# ATmega32C1 register map
Vendor: Atmel; File version: 1.0
CPU: other r0p0, little endian, no MPU, no FPU, 4 interrupt priority bits
Registers are 8-bit, read-write, reset 0x0 unless marked. A register's access mark holds for its fields unless they carry their own. Offsets are from the block's base; [hi:lo] are bit positions; {n}, {i} and the like mark numbered series.

## PORTB — I/O Port
Base 0x00000023
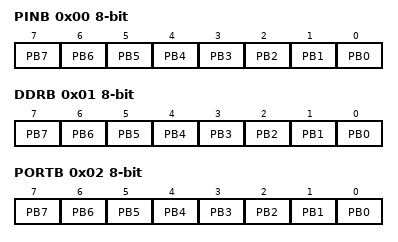
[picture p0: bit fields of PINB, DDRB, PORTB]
0x00 PINB — Port B Input Pins
  [n] PB{n} (n=0..7) — Pin B{n}
0x01 DDRB — Port B Data Direction Register
  [n] PB{n} (n=0..7) — Pin B{n}
0x02 PORTB — Port B Data Register
  [n] PB{n} (n=0..7) — Pin B{n}

## PORTC — I/O Port
Base 0x00000026
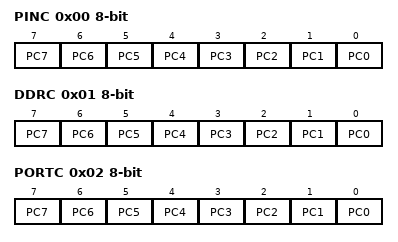
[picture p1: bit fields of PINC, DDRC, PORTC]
0x00 PINC — Port C Input Pins
  [n] PC{n} (n=0..7) — Pin C{n}
0x01 DDRC — Port C Data Direction Register
  [n] PC{n} (n=0..7) — Pin C{n}
0x02 PORTC — Port C Data Register
  [n] PC{n} (n=0..7) — Pin C{n}

## PORTD — I/O Port
Base 0x00000029
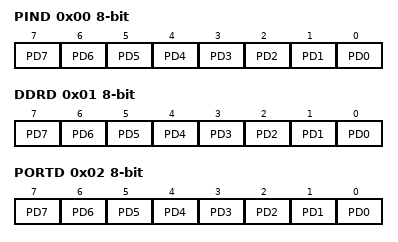
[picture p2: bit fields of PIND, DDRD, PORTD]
0x00 PIND — Port D Input Pins
  [n] PD{n} (n=0..7) — Pin D{n}
0x01 DDRD — Port D Data Direction Register
  [n] PD{n} (n=0..7) — Pin D{n}
0x02 PORTD — Port D Data Register
  [n] PD{n} (n=0..7) — Pin D{n}

## PORTE — I/O Port
Base 0x0000002C
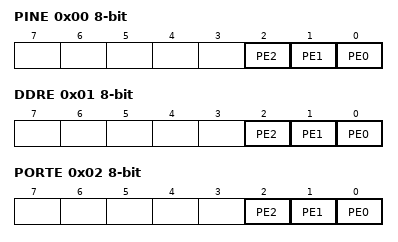
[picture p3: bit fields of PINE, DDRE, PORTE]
0x00 PINE — Port E Input Pins
  [2] PE2 — Pin E2
  [1] PE1 — Pin E1
  [0] PE0 — Pin E0
0x01 DDRE — Port E Data Direction Register
  [2] PE2 — Pin E2
  [1] PE1 — Pin E1
  [0] PE0 — Pin E0
0x02 PORTE — Port E Data Register
  [2] PE2 — Pin E2
  [1] PE1 — Pin E1
  [0] PE0 — Pin E0

## SPI — Serial Peripheral Interface
Base 0x0000004C
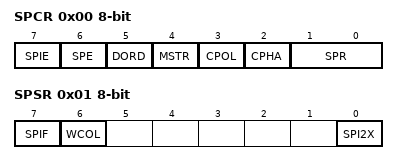
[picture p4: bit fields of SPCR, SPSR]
0x00 SPCR — SPI Control Register
  [7] SPIE — SPI Interrupt Enable
  [6] SPE — SPI Enable
  [5] DORD — Data Order
  [4] MSTR — Master/Slave Select
  [3] CPOL — Clock polarity
  [2] CPHA — Clock Phase
  [1:0] SPR — SPI Clock Rate Selects
    0=fosc/4; 1=fosc/16; 2=fosc/64; 3=fosc/128
0x01 SPSR — SPI Status Register
  [7] SPIF — SPI Interrupt Flag
  [6] WCOL — Write Collision Flag
  [0] SPI2X — Double SPI Speed Bit
0x02 SPDR — SPI Data Register
  [7:0] SPDR — SPI Data bits

## TC0 — Timer/Counter, 8-bit
Base 0x00000035
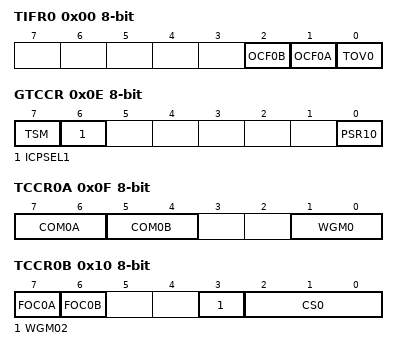
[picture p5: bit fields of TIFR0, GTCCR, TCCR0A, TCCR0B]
0x00 TIFR0 — Timer/Counter0 Interrupt Flag register
  [2] OCF0B — Timer/Counter0 Output Compare Flag 0B
  [1] OCF0A — Timer/Counter0 Output Compare Flag 0A
  [0] TOV0 — Timer/Counter0 Overflow Flag
0x0E GTCCR — General Timer/Counter Control Register
  [7] TSM — Timer/Counter Synchronization Mode
  [6] ICPSEL1 — Timer1 Input Capture Selection Bit
  [0] PSR10 — Prescaler Reset Timer/Counter1 and Timer/Counter0
0x0F TCCR0A — Timer/Counter Control Register A
  [7:6] COM0A — Compare Output Mode, Phase Correct PWM Mode
  [5:4] COM0B — Compare Output Mode, Fast PWm
  [1:0] WGM0 — Waveform Generation Mode
0x10 TCCR0B — Timer/Counter Control Register B
  [7] FOC0A — Force Output Compare A
  [6] FOC0B — Force Output Compare B
  [3] WGM02
  [2:0] CS0 — Clock Select
    0=No Clock Source (Stopped); 1=Running, No Prescaling; 2=Running, CLK/8; 3=Running, CLK/64; 4=Running, CLK/256; 5=Running, CLK/1024; 6=Running, ExtClk Tx Falling Edge; 7=Running, ExtClk Tx Rising Edge
0x11 TCNT0 — Timer/Counter0
  [7:0] TCNT0 — Timer/Counter0 bits
0x12 OCR0A — Timer/Counter0 Output Compare Register
  [7:0] OCR0A — Timer/Counter0 Output Compare bits
0x13 OCR0B — Timer/Counter0 Output Compare Register
  [7:0] OCR0B — Timer/Counter0 Output Compare bits
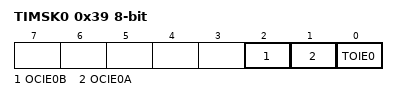
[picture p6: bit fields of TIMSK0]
0x39 TIMSK0 — Timer/Counter0 Interrupt Mask Register
  [2] OCIE0B — Timer/Counter0 Output Compare Match B Interrupt Enable
  [1] OCIE0A — Timer/Counter0 Output Compare Match A Interrupt Enable
  [0] TOIE0 — Timer/Counter0 Overflow Interrupt Enable

## TC1 — Timer/Counter, 16-bit
Base 0x00000036
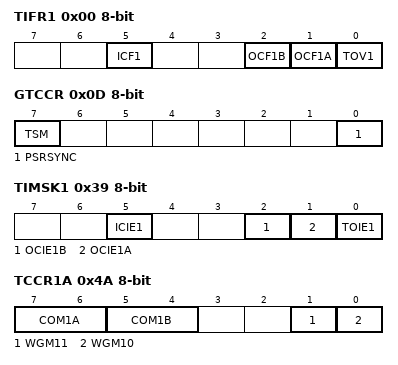
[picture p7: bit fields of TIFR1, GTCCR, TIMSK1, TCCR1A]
0x00 TIFR1 — Timer/Counter Interrupt Flag register
  [5] ICF1 — Input Capture Flag 1
  [2] OCF1B — Output Compare Flag 1B
  [1] OCF1A — Output Compare Flag 1A
  [0] TOV1 — Timer/Counter1 Overflow Flag
0x0D GTCCR — General Timer/Counter Control Register
  [7] TSM — Timer/Counter Synchronization Mode
  [0] PSRSYNC — Prescaler Reset Timer/Counter1 and Timer/Counter0
0x39 TIMSK1 — Timer/Counter Interrupt Mask Register
  [5] ICIE1 — Timer/Counter1 Input Capture Interrupt Enable
  [2] OCIE1B — Timer/Counter1 Output CompareB Match Interrupt Enable
  [1] OCIE1A — Timer/Counter1 Output CompareA Match Interrupt Enable
  [0] TOIE1 — Timer/Counter1 Overflow Interrupt Enable
0x4A TCCR1A — Timer/Counter1 Control Register A
  [7:6] COM1A — Compare Output Mode 1A, bits
  [5:4] COM1B — Compare Output Mode 1B, bits
  [1] WGM11 — Waveform Generation Mode
  [0] WGM10 — Waveform Generation Mode
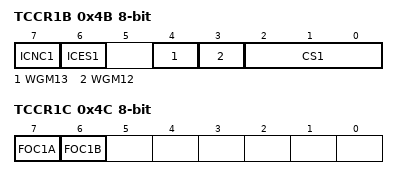
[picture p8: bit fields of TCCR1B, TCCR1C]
0x4B TCCR1B — Timer/Counter1 Control Register B
  [7] ICNC1 — Input Capture 1 Noise Canceler
  [6] ICES1 — Input Capture 1 Edge Select
  [4] WGM13 — Waveform Generation Mode
  [3] WGM12 — Waveform Generation Mode
  [2:0] CS1 — Prescaler source of Timer/Counter 1
    0=No Clock Source (Stopped); 1=Running, No Prescaling; 2=Running, CLK/8; 3=Running, CLK/64; 4=Running, CLK/256; 5=Running, CLK/1024; 6=Running, ExtClk Tx Falling Edge; 7=Running, ExtClk Tx Rising Edge
0x4C TCCR1C — Timer/Counter1 Control Register C
  [7] FOC1A, [6] FOC1B
0x4E TCNT1 16-bit (reset mask 0xFF) — Timer/Counter1 Bytes
  [15:0] TCNT1 — Timer/Counter1 bits
0x50 ICR1 16-bit (reset mask 0xFF) — Timer/Counter1 Input Capture Register Bytes
  [15:0] ICR1 — Timer/Counter1 Input Capture bits
0x52 OCR1A 16-bit (reset mask 0xFF) — Timer/Counter1 Output Compare Register Bytes
  [15:0] OCR1A — Timer/Counter1 Output Compare bits
0x54 OCR1B 16-bit (reset mask 0xFF) — Timer/Counter1 Output Compare Register Bytes
  [15:0] OCR1B — Timer/Counter1 Output Compare bits

## WDT — Watchdog Timer
Base 0x00000060
0x00 WDTCSR — Watchdog Timer Control Register
  [7] WDIF — Watchdog Timeout Interrupt Flag
  [6] WDIE — Watchdog Timeout Interrupt Enable
  [4] WDCE — Watchdog Change Enable
  [3] WDE — Watch Dog Enable
  [5:0] WDP — Watchdog Timer Prescaler Bits
    0=Oscillator Cycles 2K; 1=Oscillator Cycles 4K; 2=Oscillator Cycles 8K; 3=Oscillator Cycles 16K; 4=Oscillator Cycles 32K; 5=Oscillator Cycles 64K; 6=Oscillator Cycles 128K; 7=Oscillator Cycles 256K
